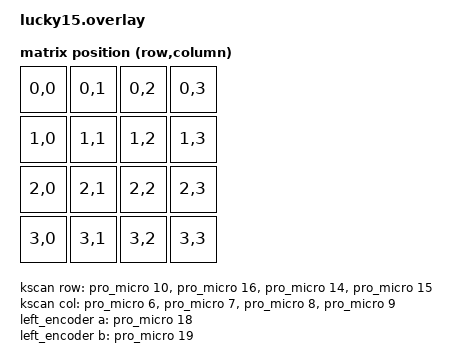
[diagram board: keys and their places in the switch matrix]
// This file was generated from a template. Edit it to match your keyboard.
// See https://zmk.dev/docs/development/hardware-integration/new-shield for more
// instructions.

#include <dt-bindings/zmk/matrix_transform.h>

#include "lucky15-layouts.dtsi"

/ {
    chosen {
        zmk,kscan = &kscan;
        zmk,matrix-transform = &default_transform;
        zmk,physical-layout = &default_layout;
    };

    kscan: kscan {
        // If the hardware does not use a switch matrix, change this to the
        // appropriate driver and update the properties below to match.
        // See https://zmk.dev/docs/config/kscan for supported key scan drivers.
        compatible = "zmk,kscan-gpio-matrix";
        // Set this to "col2row" or "row2col" to match the hardware. If using
        // "row2col", change the col-gpios to (GPIO_ACTIVE_HIGH | GPIO_PULL_DOWN)
        // and the row-gpios to GPIO_ACTIVE_HIGH.
        diode-direction = "row2col";
        wakeup-source;

        // Replace these comments with the GPIO pins in the matrix.
        // See https://zmk.dev/docs/development/hardware-integration/new-shield#shield-overlays
        col-gpios
            = <&pro_micro 6 (GPIO_ACTIVE_HIGH | GPIO_PULL_DOWN)>,
              <&pro_micro 7 (GPIO_ACTIVE_HIGH | GPIO_PULL_DOWN)>,
              <&pro_micro 8 (GPIO_ACTIVE_HIGH | GPIO_PULL_DOWN)>,
              <&pro_micro 9 (GPIO_ACTIVE_HIGH | GPIO_PULL_DOWN)>;
              

        row-gpios
            = <&pro_micro 10 GPIO_ACTIVE_HIGH>,
              <&pro_micro 16 GPIO_ACTIVE_HIGH>,
              <&pro_micro 14 GPIO_ACTIVE_HIGH>,
              <&pro_micro 15 GPIO_ACTIVE_HIGH>;
    };

    default_transform: default_transform {
        // See https://zmk.dev/docs/development/hardware-integration/new-shield#matrix-transform
        // for how to configure this
        compatible = "zmk,matrix-transform";
        columns = <4>;
        rows = <4>;

        map = <
            RC(0, 0) RC(0, 1) RC(0, 2) RC(0, 3)
            RC(1, 0) RC(1, 1) RC(1, 2) RC(1, 3)
            RC(2, 0) RC(2, 1) RC(2, 2) RC(2, 3)
            RC(3, 0) RC(3, 1) RC(3, 2) RC(3, 3)
        >;
    };
    left_encoder: encoder_left {
        compatible = "alps,ec11";
        // KiCad pins 17 (ENCO_A) & 18 (ENCO_B) -> Silkscreen pins 18 & 19
        a-gpios = <&pro_micro 18 (GPIO_ACTIVE_HIGH | GPIO_PULL_UP)>;
        b-gpios = <&pro_micro 19 (GPIO_ACTIVE_HIGH | GPIO_PULL_UP)>;
        steps = <80>;
    };

    sensors: sensors {
        compatible = "zmk,keymap-sensors";
        sensors = <&left_encoder>;
        triggers-per-rotation = <20>;
    };
};
&pro_micro_i2c {
    status = "okay";

    oled: oled@3c {
        compatible = "solomon,ssd1306fb";
        reg = <0x3c>;
        width = <128>;
        height = <32>;
        segment-offset = <0>;
        page-offset = <0>;
        display-offset = <0>;
        multiplex-ratio = <31>;
        com-sequential;
        inversion-on;
        prechargep = <0x22>;
    };
};
